# STM32N655 register map
File version: 1.0
CPU: CM55 r0p1, little endian, no MPU, FPU, vendor SysTick, 8 interrupt priority bits
Registers are 32-bit, read-write, reset 0x0 unless marked. A register's access mark holds for its fields unless they carry their own. Offsets are from the block's base; [hi:lo] are bit positions.

## USART1 — Universal synchronous/asynchronous receiver transmitter
Base 0x42001000
Same registers: USART2 0x40004400, USART3 0x40004800, UART4 0x40004C00, UART5 0x40005000, UART7 0x40007800, UART8 0x40007C00, USART6 0x42001400, UART9 0x42001800, USART10 0x42001C00, USART2_S 0x50004400, USART3_S 0x50004800, UART4_S 0x50004C00, UART5_S 0x50005000, UART7_S 0x50007800, UART8_S 0x50007C00, USART1_S 0x52001000, USART6_S 0x52001400, UART9_S 0x52001800, USART10_S 0x52001C00
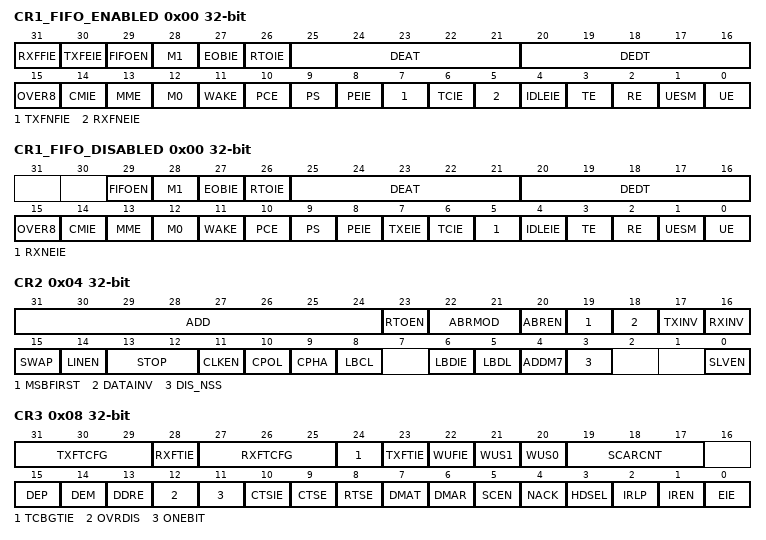
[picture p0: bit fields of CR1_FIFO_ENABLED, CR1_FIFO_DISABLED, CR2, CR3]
0x00 CR1_FIFO_ENABLED — USART control register 1 [alternate]
  [31] RXFFIE — RXFIFO Full interrupt enable
  [30] TXFEIE — TXFIFO empty interrupt enable
  [29] FIFOEN — FIFO mode enable
  [28] M1 — Word length
  [27] EOBIE — End of Block interrupt enable
  [26] RTOIE — Receiver timeout interrupt enable
  [25:21] DEAT — Driver Enable assertion time
  [20:16] DEDT — Driver Enable deassertion time
  [15] OVER8 — Oversampling mode
  [14] CMIE — Character match interrupt enable
  [13] MME — Mute mode enable
  [12] M0 — Word length
  [11] WAKE — Receiver wakeup method
  [10] PCE — Parity control enable
  [9] PS — Parity selection
  [8] PEIE — PE interrupt enable
  [7] TXFNFIE — TXFIFO not full interrupt enable
  [6] TCIE — Transmission complete interrupt enable
  [5] RXFNEIE — RXFIFO not empty interrupt enable
  [4] IDLEIE — IDLE interrupt enable
  [3] TE — Transmitter enable
  [2] RE — Receiver enable
  [1] UESM — USART enable in low-power mode
  [0] UE — USART enable
0x00 CR1_FIFO_DISABLED (alternate view of CR1_FIFO_ENABLED) — USART control register 1 [alternate]
  [29] FIFOEN — FIFO mode enable
  [28] M1 — Word length
  [27] EOBIE — End of Block interrupt enable
  [26] RTOIE — Receiver timeout interrupt enable
  [25:21] DEAT — Driver Enable assertion time
  [20:16] DEDT — Driver Enable deassertion time
  [15] OVER8 — Oversampling mode
  [14] CMIE — Character match interrupt enable
  [13] MME — Mute mode enable
  [12] M0 — Word length
  [11] WAKE — Receiver wakeup method
  [10] PCE — Parity control enable
  [9] PS — Parity selection
  [8] PEIE — PE interrupt enable
  [7] TXEIE — Transmit data register empty
  [6] TCIE — Transmission complete interrupt enable
  [5] RXNEIE — Receive data register not empty
  [4] IDLEIE — IDLE interrupt enable
  [3] TE — Transmitter enable
  [2] RE — Receiver enable
  [1] UESM — USART enable in low-power mode
  [0] UE — USART enable
0x04 CR2 — USART control register 2
  [31:24] ADD — Address of the USART node
  [23] RTOEN — Receiver timeout enable
  [22:21] ABRMOD — Auto baud rate mode
  [20] ABREN — Auto baud rate enable
  [19] MSBFIRST — Most significant bit first
  [18] DATAINV — Binary data inversion
  [17] TXINV — TX pin active level inversion
  [16] RXINV — RX pin active level inversion
  [15] SWAP — Swap TX/RX pins
  [14] LINEN — LIN mode enable
  [13:12] STOP — stop bits
  [11] CLKEN — Clock enable
  [10] CPOL — Clock polarity
  [9] CPHA — Clock phase
  [8] LBCL — Last bit clock pulse
  [6] LBDIE — LIN break detection interrupt enable
  [5] LBDL — LIN break detection length
  [4] ADDM7 — 7-bit Address Detection/4-bit Address Detection
  [3] DIS_NSS — When the DIS_NSS bit is set, the NSS pin input is ignored.
  [0] SLVEN — Synchronous Slave mode enable
0x08 CR3 — USART control register 3
  [31:29] TXFTCFG — TXFIFO threshold configuration
  [28] RXFTIE — RXFIFO threshold interrupt enable
  [27:25] RXFTCFG — Receive FIFO threshold configuration
  [24] TCBGTIE — Transmission Complete before guard time, interrupt enable
  [23] TXFTIE — TXFIFO threshold interrupt enable
  [22] WUFIE — Wakeup from low-power mode interrupt enable
  [21] WUS1 — Wakeup from low-power mode interrupt flag selection
  [20] WUS0 — Wakeup from low-power mode interrupt flag selection
  [19:17] SCARCNT — Smartcard auto-retry count
  [15] DEP — Driver enable polarity selection
  [14] DEM — Driver enable mode
  [13] DDRE — DMA Disable on Reception Error
  [12] OVRDIS — Overrun Disable
  [11] ONEBIT — One sample bit method enable
  [10] CTSIE — CTS interrupt enable
  [9] CTSE — CTS enable
  [8] RTSE — RTS enable
  [7] DMAT — DMA enable transmitter
  [6] DMAR — DMA enable receiver
  [5] SCEN — Smartcard mode enable
  [4] NACK — Smartcard NACK enable
  [3] HDSEL — Half-duplex selection
  [2] IRLP — IrDA low-power
  [1] IREN — IrDA mode enable
  [0] EIE — Error interrupt enable
0x0C BRR — USART baud rate register
  [15:0] BRR — USART baud rate
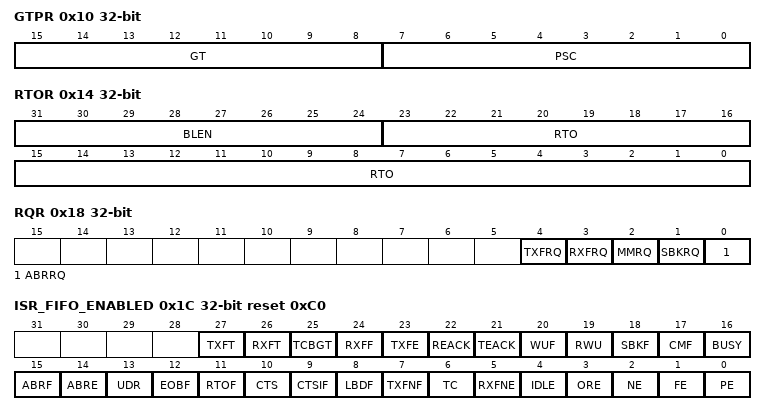
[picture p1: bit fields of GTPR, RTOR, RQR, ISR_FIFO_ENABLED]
0x10 GTPR — USART guard time and prescaler register
  [15:8] GT — Guard time value
  [7:0] PSC — Prescaler value
0x14 RTOR — USART receiver timeout register
  [31:24] BLEN — Block Length
  [23:0] RTO — Receiver timeout value
0x18 RQR wo — USART request register
  [4] TXFRQ — Transmit data flush request
  [3] RXFRQ — Receive data flush request
  [2] MMRQ — Mute mode request
  [1] SBKRQ — Send break request
  [0] ABRRQ — Auto baud rate request
0x1C ISR_FIFO_ENABLED ro reset 0xC0 (reset mask 0xF00FFFFF) — USART interrupt and status register [alternate]
  [27] TXFT — TXFIFO threshold flag
  [26] RXFT — RXFIFO threshold flag
  [25] TCBGT — Transmission complete before guard time flag
  [24] RXFF — RXFIFO Full
  [23] TXFE — TXFIFO Empty
  [22] REACK — Receive enable acknowledge flag
  [21] TEACK — Transmit enable acknowledge flag
  [20] WUF — Wakeup from low-power mode flag
  [19] RWU — Receiver wakeup from Mute mode
  [18] SBKF — Send break flag
  [17] CMF — Character match flag
  [16] BUSY — Busy flag
  [15] ABRF — Auto baud rate flag
  [14] ABRE — Auto baud rate error
  [13] UDR — SPI slave underrun error flag
  [12] EOBF — End of block flag
  [11] RTOF — Receiver timeout
  [10] CTS — CTS flag
  [9] CTSIF — CTS interrupt flag
  [8] LBDF — LIN break detection flag
  [7] TXFNF — TXFIFO not full
  [6] TC — Transmission complete
  [5] RXFNE — RXFIFO not empty
  [4] IDLE — Idle line detected
  [3] ORE — Overrun error
  [2] NE — Noise detection flag
  [1] FE — Framing error
  [0] PE — Parity error
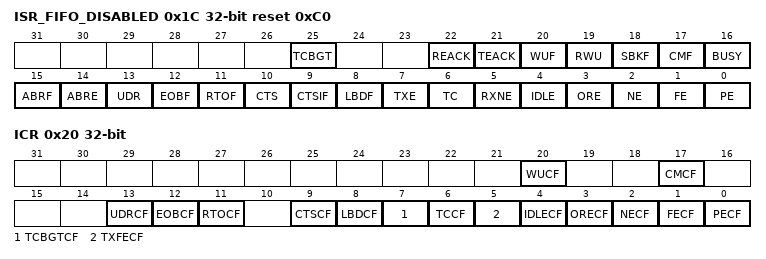
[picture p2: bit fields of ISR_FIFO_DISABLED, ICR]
0x1C ISR_FIFO_DISABLED ro reset 0xC0 (reset mask 0xF00FFFFF) (alternate view of ISR_FIFO_ENABLED) — USART interrupt and status register [alternate]
  [25] TCBGT — Transmission complete before guard time flag
  [22] REACK — Receive enable acknowledge flag
  [21] TEACK — Transmit enable acknowledge flag
  [20] WUF — Wakeup from low-power mode flag
  [19] RWU — Receiver wakeup from Mute mode
  [18] SBKF — Send break flag
  [17] CMF — Character match flag
  [16] BUSY — Busy flag
  [15] ABRF — Auto baud rate flag
  [14] ABRE — Auto baud rate error
  [13] UDR — SPI slave underrun error flag
  [12] EOBF — End of block flag
  [11] RTOF — Receiver timeout
  [10] CTS — CTS flag
  [9] CTSIF — CTS interrupt flag
  [8] LBDF — LIN break detection flag
  [7] TXE — Transmit data register empty
  [6] TC — Transmission complete
  [5] RXNE — Read data register not empty
  [4] IDLE — Idle line detected
  [3] ORE — Overrun error
  [2] NE — Noise detection flag
  [1] FE — Framing error
  [0] PE — Parity error
0x20 ICR wo — USART interrupt flag clear register
  [20] WUCF — Wakeup from low-power mode clear flag
  [17] CMCF — Character match clear flag
  [13] UDRCF — SPI slave underrun clear flag
  [12] EOBCF — End of block clear flag
  [11] RTOCF — Receiver timeout clear flag
  [9] CTSCF — CTS clear flag
  [8] LBDCF — LIN break detection clear flag
  [7] TCBGTCF — Transmission complete before Guard time clear flag
  [6] TCCF — Transmission complete clear flag
  [5] TXFECF — TXFIFO empty clear flag
  [4] IDLECF — Idle line detected clear flag
  [3] ORECF — Overrun error clear flag
  [2] NECF — Noise detected clear flag
  [1] FECF — Framing error clear flag
  [0] PECF — Parity error clear flag
0x24 RDR ro — USART receive data register
  [8:0] RDR — Receive data value
0x28 TDR — USART transmit data register
  [8:0] TDR — Transmit data value
0x2C PRESC — USART prescaler register
  [3:0] PRESCALER — Clock prescaler
